# nrf54l15_enga_application register map
Vendor: Nordic Semiconductor; Series: nrf54l; File version: 1
CPU: CM33 r0p4, little endian, MPU, FPU, 3 interrupt priority bits, 176 interrupts, 4 SAU regions
Registers are 32-bit, read-write, reset 0x0 unless marked. A register's access mark holds for its fields unless they carry their own. Offsets are from the block's base; [hi:lo] are bit positions; {n}, {i} and the like mark numbered series; 'fields as' and 'values as' point back to an identical list.

## TPIU_NS — Trace Port Interface Unit
Base 0xE0040000
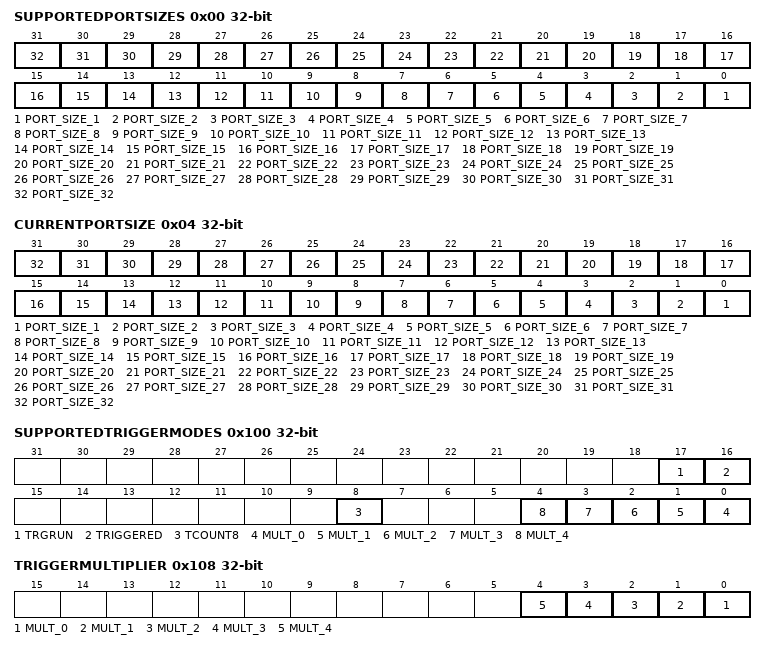
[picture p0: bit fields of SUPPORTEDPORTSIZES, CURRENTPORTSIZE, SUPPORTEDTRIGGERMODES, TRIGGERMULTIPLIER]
0x00 SUPPORTEDPORTSIZES — Each bit location is a single port size that is supported on the device.
  [n-1] PORT_SIZE_{n} (n=1..32) — Indicates whether the TPIU supports port size of {n}-bit.
    0=NotSupported (Port size {n} is not supported.); 1=Supported (Port size {n} is supported.)
0x04 CURRENTPORTSIZE — Each bit location is a single port size. One bit can be set, and indicates the current port size.
  [n-1] PORT_SIZE_{n} (n=1..32) — Indicates which port size is currently selected.
    0=NotSelected (Port size {n} is not selected.); 1=Selected (Port size {n} is selected.)
0x100 SUPPORTEDTRIGGERMODES — The Supported_trigger_modes register indicates the implemented trigger counter multipliers and other supported features of the trigger system.
  [17] TRGRUN — A trigger has occurred but the counter is not at 0.
    0=NotOccured (Either a trigger has not occurred or the counter is at 0.); 1=Occured (A trigger has occurred but the counter is not at 0.)
  [16] TRIGGERED — A trigger has occurred and the counter has reached 0.
    0=NotOccured (Trigger has not occurred.); 1=Occured (Trigger has occurred.)
  [8] TCOUNT8 — Indicates whether an 8-bit wide counter register is implemented.
    0=NotImplemented (An 8-bit wide counter register is implemented.); 1=Implemented (An 8-bit wide counter register is implemented.)
  [n] MULT_{n} (n=0..4) — Indicates whether multiplying the trigger counter by 2^({n}+1) is supported.
    0=NotSelected (Multiplying the trigger counter by 2^({n}+1) is supported.); 1=Selected (Multiplying the trigger counter by 2^({n}+1) is supported.)
0x104 TRIGGERCOUNTERVALUE — The Trigger_counter_value register enables delaying the indication of triggers to any external connected trace capture or storage devices.
  [7:0] TrigCount — 8-bit counter value for the number of words to be output from the formatter before a trigger is inserted.
0x108 TRIGGERMULTIPLIER — The Trigger_multiplier register contains the selectors for the trigger counter multiplier.
  [all] fields
    0=Disabled (Multiplier disabled.); 1=Enabled (Multiplier enabled.)
  [n] MULT_{n} (n=0..4) — Multiply the Trigger Counter by 2^n.
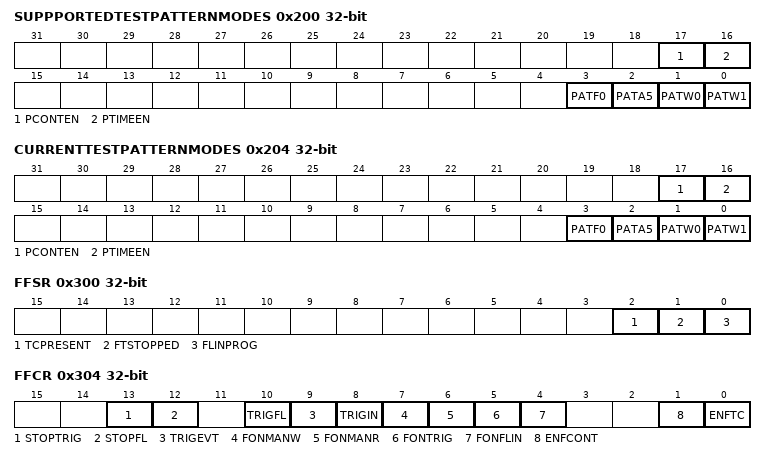
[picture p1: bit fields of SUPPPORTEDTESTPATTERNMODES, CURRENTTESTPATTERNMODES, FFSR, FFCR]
0x200 SUPPPORTEDTESTPATTERNMODES — The Supported_test_pattern_modes register provides a set of known bit sequences or patterns that can be output over the trace port and can be detected by the TPA or other associated trace capture device.
  [17] PCONTEN — Indicates whether continuous mode is supported.
    0=NotSupported (Mode is not supported.); 1=Supported (Mode is supported.)
  [16] PTIMEEN — Indicates whether timed mode is supported.
    values as PCONTEN
  [3] PATF0 — Indicates whether the FF/00 pattern is supported as output over the trace port.
    0=NotSupported (Test pattern is not supported.); 1=Supported (Test pattern is supported.)
  [2] PATA5 — Indicates whether the AA/55 pattern is supported as output over the trace port.
    values as PATF0
  [1] PATW0 — Indicates whether the walking 0s pattern is supported as output over the trace port.
    values as PATF0
  [0] PATW1 — Indicates whether the walking 1s pattern is supported as output over the trace port.
    values as PATF0
0x204 CURRENTTESTPATTERNMODES — Current_test_pattern_mode indicates the current test pattern or mode selected.
  [17] PCONTEN — Indicates whether continuous mode is supported.
    0=Disabled (Mode is disabled.); 1=Enabled (Mode is enabled.)
  [16] PTIMEEN — Indicates whether timed mode is supported.
    0=Disabled (Mode is disabled.); 1=Enabled (Mode is enabled.)
  [3] PATF0 — Indicates whether the FF/00 pattern is supported as output over the trace port.
    0=Disabled (Test pattern is disabled.); 1=Enabled (Test pattern is enabled.)
  [2] PATA5 — Indicates whether the AA/55 pattern is supported as output over the trace port.
    values as PATF0
  [1] PATW0 — Indicates whether the walking 0s pattern is supported as output over the trace port.
    values as PATF0
  [0] PATW1 — Indicates whether the walking 1s pattern is supported as output over the trace port.
    values as PATF0
0x208 TPRCR — The TPRCR register is an 8-bit counter start value that is decremented. A write sets the initial counter value and a read returns the programmed value.
  [7:0] PATTCOUNT — 8-bit counter value to indicate the number of traceclkin cycles for which a pattern runs before it switches to the next pattern.
0x300 FFSR — The FFSR register indicates the current status of the formatter and flush features available in the TPIU.
  [2] TCPRESENT — Indicates whether the TRACECTL pin is available for use.
    0=NotPresent (TRACECTL pin is not present.); 1=Present (TRACECTL pin is present.)
  [1] FTSTOPPED — The formatter has received a stop request signal and all trace data and post-amble is sent. Any additional trace data on the ATB interface is ignored and atreadys goes HIGH.
    0=Running (Formatter has not stopped.); 1=Stopped (Formatter has stopped.)
  [0] FLINPROG — Flush in progress.
    0=NotInProgress (A flush is not in progress.); 1=InProgress (A flush is in progress.)
0x304 FFCR — The FFCR register controls the generation of stop, trigger, and flush events.
  [all] fields
    0=Disabled (The formatting feature is disabled.); 1=Enabled (The formatting feature is enabled.)
  [13] STOPTRIG — Stops the formatter after a trigger event is observed. Reset to disabled or 0.
  [12] STOPFL — Forces the FIFO to drain off any part-completed packets.
  [10] TRIGFL — Indicates a trigger when flush completion on afreadys is returned.
  [9] TRIGEVT — Indicates a trigger on a trigger event.
  [8] TRIGIN — Indicates a trigger when trigin is asserted.
  [7] FONMANW — Generates a flush. This bit is set to 1 when this flush is serviced.
  [6] FONMANR — Generates a flush. This bit is set to 0 when this flush is serviced.
  [5] FONTRIG — Initiates a manual flush of data in the system when a trigger event occurs.
  [4] FONFLIN — Enables the use of the flushin connection.
  [1] ENFCONT — Is embedded in trigger packets and indicates that no cycle is using sync packets.
  [0] ENFTC — Do not embed triggers into the formatted stream. Trace disable cycles and triggers are indicated by tracectl, where present.
0x308 FSCR — The FSCR register enables the frequency of synchronization information to be optimized to suit the Trace Port Analyzer (TPA) capture buffer size.
  [11:0] CYCCOUNT — 12-bit counter reload value. Indicates the number of complete frames between full synchronization packets.
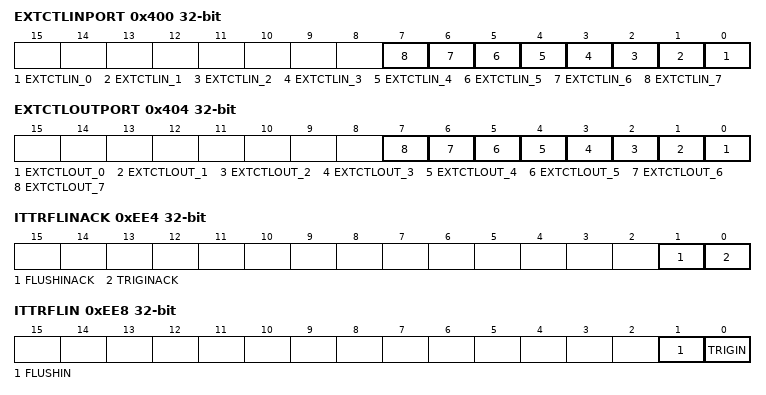
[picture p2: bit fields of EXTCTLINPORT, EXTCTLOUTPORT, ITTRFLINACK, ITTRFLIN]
0x400 EXTCTLINPORT — Two ports can be used as a control and feedback mechanism for any serializers, pin sharing multiplexers, or other solutions that might be added to the trace output pins either for pin control or a high-speed trace port solution.
  [n] EXTCTLIN_{n} (n=0..7) — EXTCTL inputs.
    0=Low (Input EXTCTL{n} is low.); 1=High (Input EXTCTL{n} is high.)
0x404 EXTCTLOUTPORT — Two ports can be used as a control and feedback mechanism for any serializers, pin sharing multiplexers, or other solutions that might be added to the trace output pins either for pin control or a high speed trace port solution. These ports are raw register banks that sample or export the corresponding external pins.
  [n] EXTCTLOUT_{n} (n=0..7) — EXTCTL outputs.
    0=Low (Output EXTCTL{n} is low.); 1=High (Output EXTCTL{n} is high.)
0xEE4 ITTRFLINACK — The ITTRFLINACK register enables control of the triginack and flushinack outputs from the TPIU.
  [1] FLUSHINACK — Sets the value of flushinack.
    0=Low (Pin is logic 0.); 1=High (Pin is logic 1.)
  [0] TRIGINACK — Sets the value of triginack.
    0=Low (Pin is logic 0.); 1=High (Pin is logic 1.)
0xEE8 ITTRFLIN — The ITTRFLIN register contains the values of the flushin and trigin inputs to the TPIU.
  [1] FLUSHIN — Reads the value of flushin.
    0=Low (Pin is logic 0.); 1=High (Pin is logic 1.)
  [0] TRIGIN — Reads the value of trigin.
    0=Low (Pin is logic 0.); 1=High (Pin is logic 1.)
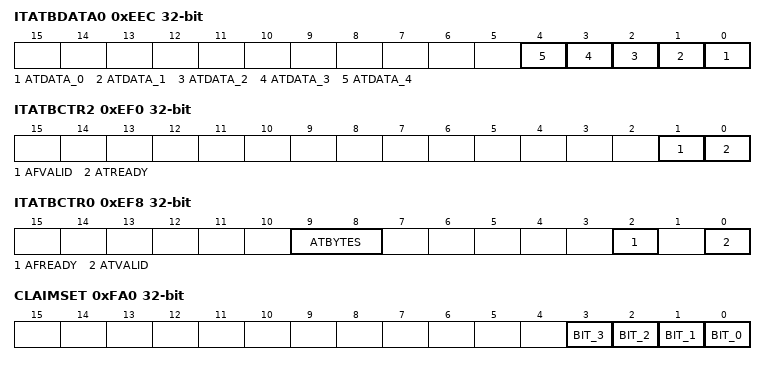
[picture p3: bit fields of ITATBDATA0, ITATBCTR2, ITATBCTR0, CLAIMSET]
0xEEC ITATBDATA0 — The ITATBDATA0 register contains the value of the atdatas inputs to the TPIU. The values are valid only when atvalids is HIGH.
  [all] fields
    0=Low (Pin is logic 0.); 1=High (Pin is logic 1.)
  [n] ATDATA_{n} (n=0..4) — A read access returns the value of a pin on atdatas_x of the enabled port. A write access writes to the corresponding atdatam pin of the enabled port.
0xEF0 ITATBCTR2 — Enables control of the atreadys and afvalids outputs of the TPIU.
  [1] AFVALID — Sets the value of atready.
    0=Low (Pin is logic 0.); 1=High (Pin is logic 1.)
  [0] ATREADY — Sets the value of afvalid.
    0=Low (Pin is logic 0.); 1=High (Pin is logic 1.)
0xEF4 ITATBCTR1 — The ITATBCTR1 register contains the value of the atids input to the TPIU. This is only valid when atvalids is HIGH.
  [6:0] ATID — Reads the value of atids.
    0=Low (Pin is logic 0.); 1=High (Pin is logic 1.)
0xEF8 ITATBCTR0 — The ITATBCTR0 register captures the values of the atvalids, afreadys, and atbytess inputs to the TPIU. To ensure the integration registers work correctly in a system, the value of atbytess is only valid when atvalids, bit[0], is HIGH.
  [all] fields
    0=Low (Pin is logic 0.); 1=High (Pin is logic 1.)
  [9:8] ATBYTES — Reads the value of atbytess.
  [2] AFREADY — Reads the value of afreadys.
  [0] ATVALID — Reads the value of atvalids.
0xF00 ITCTRL — Used to enable topology detection. This register enables the component to switch from a functional mode, the default behavior, to integration mode where the inputs and outputs of the component can be directly controlled for integration testing and topology solving.
  [0] INTEGRATIONMODE — Enables the component to switch from functional mode to integration mode and back. If no integration functionality is implemented, this register must read as zero.
    0=Disabled (Integration mode is disabled.); 1=Enabled (Integration mode is Enabled.)
0xFA0 CLAIMSET — Software can use the claim tag to coordinate application and debugger access to trace unit functionality. The claim tags have no effect on the operation of the component. The CLAIMSET register sets bits in the claim tag, and determines the number of claim bits implemented.
  [n] BIT_{n} (n=0..3) — Set claim bit {n} and check if bit is implemented or not.
    on read: 0=NotImplemented (Claim bit {n} is not implemented.); 1=Implemented (Claim bit {n} is implemented.) | on write: 1=Set (Set claim bit {n}.)
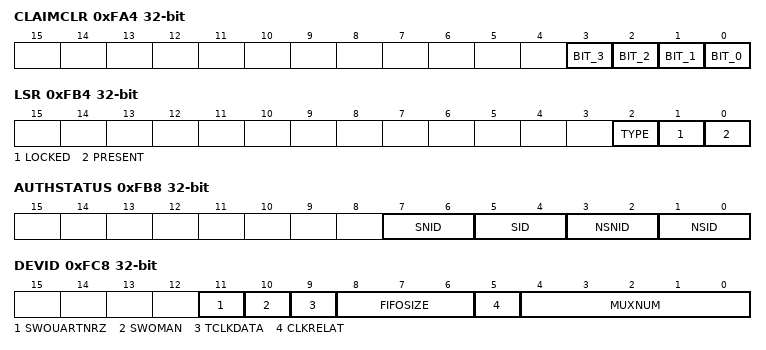
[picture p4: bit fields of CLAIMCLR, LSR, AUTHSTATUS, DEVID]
0xFA4 CLAIMCLR — Software can use the claim tag to coordinate application and debugger access to trace unit functionality. The claim tags have no effect on the operation of the component. The CLAIMCLR register sets the bits in the claim tag to 0 and determines the current value of the claim tag.
  [n] BIT_{n} (n=0..3) — Read or clear claim bit {n}.
    on read: 0=Cleared (Claim bit {n} is not set.); 1=Set (Claim bit {n} is set.) | on write: 1=Clear claim bit {n}
0xFB0 LAR — This is used to enable write access to device registers.
  [31:0] ACCESS — A write of 0xC5ACCE55 enables further write access to this device. Any other write removes write access.
    0xC5ACCE55=Unlock register interface
0xFB4 LSR — This indicates the status of the lock control mechanism. This lock prevents accidental writes by code under debug. Accesses to the extended stimulus port registers are not affected by the lock mechanism. This register must always be present although there might not be any lock access control mechanism. The lock mechanism, where present and locked, must block write accesses to any control register, except the Lock Access Register. For most components this covers all registers except for the Lock Access Register.
  [2] TYPE — Indicates if the Lock Access Register is implemented as 8-bit or 32-bit.
    0=Bits32 (This component implements a 32-bit Lock Access Register.); 1=Bits8 (This component implements an 8-bit Lock Access Register.)
  [1] LOCKED — Returns the current status of the Lock.
    0=UnLocked (Write access is allowed to this device.); 1=Locked (Write access to the component is blocked. All writes to control registers are ignored. Reads are permitted.)
  [0] PRESENT — Indicates that a lock control mechanism exists for this device.
    0=NotImplemented (No lock control mechanism exists, writes to the Lock Access Register are ignored.); 1=Implemented (Lock control mechanism is present.)
0xFB8 AUTHSTATUS — Indicates the current level of tracing permitted by the system
  [all] fields
    0=NotImplemented (The feature is not implemented.); 1=Implemented (The feature is implemented.)
  [7:6] SNID — Secure Non-Invasive Debug
  [5:4] SID — Secure Invasive Debug
  [3:2] NSNID — Non-secure Non-Invasive Debug
  [1:0] NSID — Non-secure Invasive Debug
0xFC8 DEVID ro — Indicates the capabilities of the component.
  [11] SWOUARTNRZ — Indicates whether Serial Wire Output, UART or NRZ, is supported.
    0=NotSupported (Serial Wire Output, UART or NRZ, is not supported.); 1=Supported (Serial Wire Output, UART or NRZ, is supported.)
  [10] SWOMAN — Indicates whether Serial Wire Output, Manchester encoded format, is supported.
    0=NotSupported (Serial Wire Output, Manchester encoded format, is not supported.); 1=Supported (Serial Wire Output, Manchester encoded format, is supported.)
  [9] TCLKDATA — Indicates whether trace clock plus data is supported.
    0=Supported (Trace clock and data is supported.); 1=NotSupported (Trace clock and data is not supported.)
  [8:6] FIFOSIZE — FIFO size in powers of 2.
    2=Entries4 (FIFO size of 4 entries, that is, 16 bytes.)
  [5] CLKRELAT — Indicates the relationship between atclk and traceclkin.
    0=Synchronous (atclk and traceclkin are synchronous.); 1=ASynchronous (atclk and traceclkin are asynchronous.)
  [4:0] MUXNUM — Indicates the hidden level of input multiplexing. When non-zero, this value indicates the type of multiplexing on the input to the ATB. Currently only 0x00 is supported, that is, no multiplexing is present. This value helps detect the ATB structure.
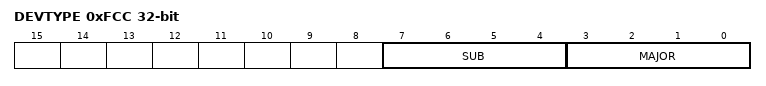
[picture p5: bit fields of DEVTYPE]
0xFCC DEVTYPE ro — The DEVTYPE register provides a debugger with information about the component when the Part Number field is not recognized. The debugger can then report this information.
  [7:4] SUB — The sub-type of the component
    1=TracePort (Indicates that this component is a trace port component.)
  [3:0] MAJOR — The main type of the component
    1=TraceSource (Peripheral is a trace sink.)
0xFD0 PIDR4 — Coresight peripheral identification registers.
{0xFE0+4i} PIDR_{i} (i=0..3) — Coresight peripheral identification registers.
{0xFF0+4i} CIDR_{i} (i=0..3) — Coresight component identification registers.
